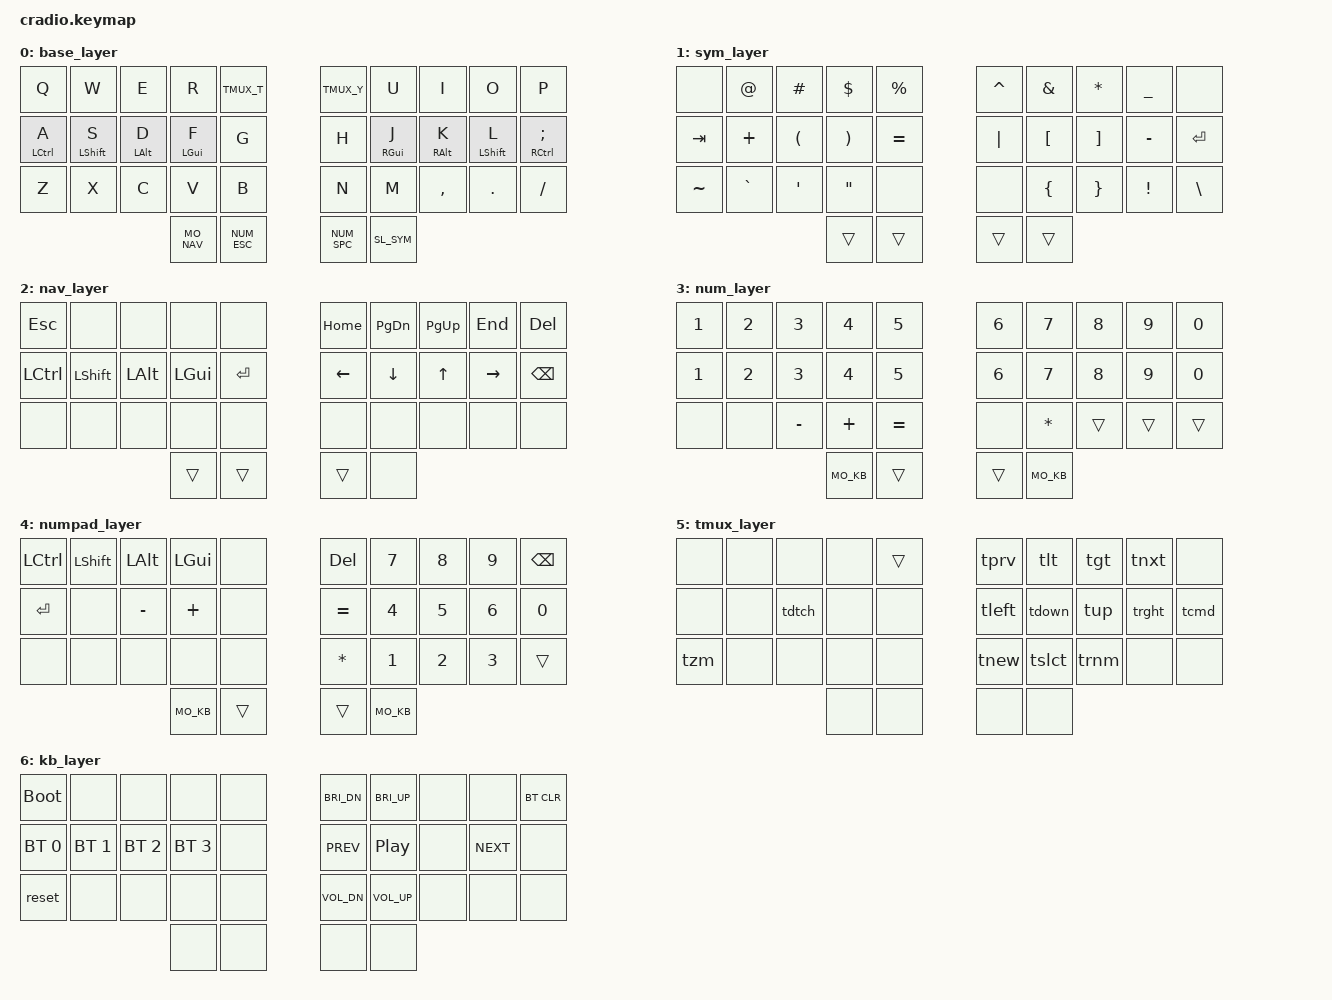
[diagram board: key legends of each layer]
/*
 * Copyright (c) 2020 The ZMK Contributors
 *
 * SPDX-License-Identifier: MIT
 */

#include <behaviors.dtsi>
#include <dt-bindings/zmk/keys.h>
#include <dt-bindings/zmk/bt.h>


// Constants
#define MO(layer) &mo layer
#define LTP(layer, kc) &lt layer kc
#define TO(layer) &to layer
#define TG(layer) &tog layer
#define SL(layer) &sl layer
#define SK(mod) &skq mod
#define _________ &trans
#define XXXXXXXXX &none

#define BOOT &bootloader
#define BTCLR &bt BT_CLR
#define BTNXT &bt BT_NXT
#define BTPRV &bt BT_PRV
#define BT_0 &bt BT_SEL 0
#define BT_1 &bt BT_SEL 1
#define BT_2 &bt BT_SEL 2
#define BT_3 &bt BT_SEL 3
#define MNEXT &kp C_NEXT
#define MPREV &kp C_PREV
#define MPLAY &kp C_PP
#define MVOLU &kp C_VOL_UP
#define MVOLD &kp C_VOL_DN
#define DBRIU &kp C_BRI_UP
#define DBRID &kp C_BRI_DN


// Helpers
#define LLT(layer, kc) &llt layer kc


// Layers
#define _BASE 0
#define _SYM 1
#define _NAV 2
#define _NUM 3
#define _NUMPAD 4
#define _TMUX 5
#define _KB 6


// Custom keycodes
#define SL_SYM SL(_SYM)
#define NUM_SPC LTP(_NUM, SPACE)
#define NUM_ESC LTP(_NUM, ESC)
#define TMUX_T LLT(_TMUX, T)
#define TMUX_Y LLT(_TMUX, Y)
#define MO_NAV MO(_NAV)
#define MO_KB MO(_KB)


// Homerow mods
#define HM_A &hm LCTRL A
#define HM_SEMI &hm RCTRL SEMI
#define HM_S &hm LSHFT S
#define HM_L &hm LSHFT L
#define HM_D &hm LALT D
#define HM_K &hm RALT K
#define HM_F &hm LGUI F
#define HM_J &hm RGUI J


// TMUX
#define TMUX_PREFIX &kp LC(B)
#define tm(NODELABEL, NODE, LABEL, USAGE) \
    NODELABEL: NODE { \
        compatible = "zmk,behavior-macro"; \
        label = LABEL; \
        #binding-cells = <0>; \
        wait-ms = <50>; \
        tap-ms = <40>; \
        bindings = <TMUX_PREFIX &kp USAGE>; \
    }


/ { 
    combos {
        compatible = "zmk,combos";

        combo_caps_word {
            timeout-ms = <50>;
            key-positions = <11 12 13>;
            bindings = <&caps_word>;
        };

        combo_esc {
            timeout-ms = <50>;
            key-positions = <16 17 18>;
            bindings = <&kp ESC>;
        };
    };

    behaviors {
        skq: sticky_key_quick_release {
            compatible = "zmk,behavior-sticky-key";
            label = "STICKY_KEY_QUICK_RELEASE";
            #binding-cells = <1>;
            bindings = <&kp>;
            release-after-ms = <750>;
            quick-release;
        };

        hm: homerow_mods {
            compatible = "zmk,behavior-hold-tap";
            label = "HOMEROW_MODS";
            #binding-cells = <2>;
            tapping-term-ms = <150>;
            flavor = "tap-preferred";
            bindings = <&kp>, <&kp>;
        };

        lhm: left_homerow_mods {
            compatible = "zmk,behavior-hold-tap";
            label = "LEFT_HOMEROW_MODS";
            #binding-cells = <2>;
            flavor = "tap-unless-interrupted";
            tapping-term-ms = <100>;                        // <---[[produces tap if held longer than tapping-term-ms]]
            bindings = <&kp>, <&kp>;
            hold-trigger-key-positions = <5 6 7 8 9 15 16 17 18 19 25 26 27 28 29>;    // <---[[right-hand keys]]
        };

        rhm: right_homerow_mods {
            compatible = "zmk,behavior-hold-tap";
            label = "RIGHT_HOMEROW_MODS";
            #binding-cells = <2>;
            flavor = "tap-unless-interrupted";
            tapping-term-ms = <100>;                        // <---[[produces tap if held longer than tapping-term-ms]]
            bindings = <&kp>, <&kp>;
            hold-trigger-key-positions = <0 1 2 3 4 10 11 12 13 14 20 21 22 23 24>;    // <---[[left-hand keys]]
        };

        llt: letter_layer_taps {
            compatible = "zmk,behavior-hold-tap";
            label = "LETTER_LAYER_TAPS";
            #binding-cells = <2>;
            tapping-term-ms = <200>;
            flavor = "tap-preferred";
            bindings = <&mo>, <&kp>;
        };

        // TMUX macro definitions
        tm(tnxt, tmux_next, "TMUX_NEXT", N);
        tm(tprv, tmux_prev, "TMUX_PREV", P);
        tm(tlt, tmux_lt, "TMUX_LT", LT);
        tm(tgt, tmux_gt, "TMUX_GT", GT);
        tm(tnew, tmux_new, "TMUX_NEW", C);
        tm(tslct, tmux_select, "TMUX_SELECT", LBKT);
        tm(tleft, tmux_left, "TMUX_LEFT", LEFT);
        tm(tdown, tmux_down, "TMUX_DOWN", DOWN);
        tm(tup, tmux_up, "TMUX_UP", UP);
        tm(trght, tmux_right, "TMUX_RIGHT", RIGHT);
        tm(tzm, tmux_zoom, "TMUX_ZOOM", Z);
        tm(tdtch, tmux_detach, "TMUX_DETACH", D);
        tm(tcmd, tmux_command, "TMUX_COMMAND", COLON);
        tm(trnm, tmux_rename, "TMUX_RENAME", COMMA);
    };

    keymap {
        compatible = "zmk,keymap";

        base_layer { bindings = <
          //┌─────────┬─────────┬─────────┬─────────┬─────────┐                            ┌─────────┬─────────┬─────────┬─────────┬─────────┐
             &kp Q     &kp W     &kp E     &kp R     TMUX_T                                 TMUX_Y    &kp U     &kp I     &kp O     &kp P 
          //├─────────┼─────────┼─────────┼─────────┼─────────┤                            ├─────────┼─────────┼─────────┼─────────┼─────────┤
             HM_A      HM_S      HM_D      HM_F      &kp G                                  &kp H     HM_J      HM_K      HM_L      HM_SEMI
          //├─────────┼─────────┼─────────┼─────────┼─────────┤                            ├─────────┼─────────┼─────────┼─────────┼─────────┤
             &kp Z     &kp X     &kp C     &kp V     &kp B                                  &kp N     &kp M     &kp COMMA &kp DOT   &kp FSLH
          //└─────────┴─────────┴─────────┴─────┬───┴─────┬───┼─────────┐        ┌─────────┼───┬─────┴───┬─────┴─────────┴─────────┴─────────┘
                                                 MO_NAV        NUM_ESC            NUM_SPC       SL_SYM
          //                                    └─────────┘   └─────────┘        └─────────┘   └─────────┘
        >; };

        sym_layer { bindings = <
          //┌─────────┬─────────┬─────────┬─────────┬─────────┐                            ┌─────────┬─────────┬─────────┬─────────┬─────────┐
             XXXXXXXXX &kp AT    &kp HASH  &kp DLLR  &kp PRCNT                              &kp CARET &kp AMPS  &kp STAR  &kp UNDER XXXXXXXXX
          //├─────────┼─────────┼─────────┼─────────┼─────────┤                            ├─────────┼─────────┼─────────┼─────────┼─────────┤
             &kp TAB   &kp PLUS  &kp LPAR  &kp RPAR  &kp EQUAL                              &kp PIPE  &kp LBKT  &kp RBKT  &kp MINUS &kp RET
          //├─────────┼─────────┼─────────┼─────────┼─────────┤                            ├─────────┼─────────┼─────────┼─────────┼─────────┤
             &kp TILDE &kp GRAVE &kp SQT   &kp DQT   XXXXXXXXX                              XXXXXXXXX &kp LBRC  &kp RBRC  &kp EXCL  &kp BSLH
          //└─────────┴─────────┴─────────┴─────┬───┴─────┬───┼─────────┐        ┌─────────┼───┬─────┴───┬─────┴─────────┴─────────┴─────────┘
                                                 _________     _________          _________     _________
          //                                    └─────────┘   └─────────┘        └─────────┘   └─────────┘
        >; };

        nav_layer { bindings = <
          //┌─────────┬─────────┬─────────┬─────────┬─────────┐                            ┌─────────┬─────────┬─────────┬─────────┬─────────┐
             &kp ESC   XXXXXXXXX XXXXXXXXX XXXXXXXXX XXXXXXXXX                              &kp HOME  &kp PG_DN &kp PG_UP &kp END   &kp DEL
          //├─────────┼─────────┼─────────┼─────────┼─────────┤                            ├─────────┼─────────┼─────────┼─────────┼─────────┤
             &kp LCTRL &kp LSHFT &kp LALT  &kp LGUI  &kp RET                                &kp LEFT  &kp DOWN  &kp UP    &kp RIGHT &kp BSPC
          //├─────────┼─────────┼─────────┼─────────┼─────────┤                            ├─────────┼─────────┼─────────┼─────────┼─────────┤
             XXXXXXXXX XXXXXXXXX XXXXXXXXX XXXXXXXXX XXXXXXXXX                              XXXXXXXXX XXXXXXXXX XXXXXXXXX XXXXXXXXX XXXXXXXXX
          //└─────────┴─────────┴─────────┴─────┬───┴─────┬───┼─────────┐        ┌─────────┼───┬─────┴───┬─────┴─────────┴─────────┴─────────┘
                                                 _________     _________          _________     XXXXXXXXX
          //                                    └─────────┘   └─────────┘        └─────────┘   └─────────┘
        >; };

        num_layer { bindings = <
          //┌─────────┬─────────┬─────────┬─────────┬─────────┐                            ┌─────────┬─────────┬─────────┬─────────┬─────────┐
             &kp N1    &kp N2    &kp N3    &kp N4    &kp N5                                 &kp N6    &kp N7    &kp N8    &kp N9    &kp N0   
          //├─────────┼─────────┼─────────┼─────────┼─────────┤                            ├─────────┼─────────┼─────────┼─────────┼─────────┤
             &kp N1    &kp N2    &kp N3    &kp N4    &kp N5                                 &kp N6    &kp N7    &kp N8    &kp N9    &kp N0   
          //├─────────┼─────────┼─────────┼─────────┼─────────┤                            ├─────────┼─────────┼─────────┼─────────┼─────────┤
             XXXXXXXXX XXXXXXXXX &kp MINUS &kp PLUS  &kp EQUAL                              XXXXXXXXX &kp STAR  _________ _________ _________
          //└─────────┴─────────┴─────────┴─────┬───┴─────┬───┼─────────┐        ┌─────────┼───┬─────┴───┬─────┴─────────┴─────────┴─────────┘
                                                 MO_KB         _________          _________     MO_KB
          //                                    └─────────┘   └─────────┘        └─────────┘   └─────────┘
        >; };

        numpad_layer { bindings = <
          //┌─────────┬─────────┬─────────┬─────────┬─────────┐                            ┌─────────┬─────────┬─────────┬─────────┬─────────┐
             &kp LCTRL &kp LSHFT &kp LALT  &kp LGUI  XXXXXXXXX                              &kp DEL   &kp N7    &kp N8    &kp N9    &kp BSPC
          //├─────────┼─────────┼─────────┼─────────┼─────────┤                            ├─────────┼─────────┼─────────┼─────────┼─────────┤
             &kp RET   XXXXXXXXX &kp MINUS &kp PLUS  XXXXXXXXX                              &kp EQUAL &kp N4    &kp N5    &kp N6    &kp N0
          //├─────────┼─────────┼─────────┼─────────┼─────────┤                            ├─────────┼─────────┼─────────┼─────────┼─────────┤
             XXXXXXXXX XXXXXXXXX XXXXXXXXX XXXXXXXXX XXXXXXXXX                              &kp STAR  &kp N1    &kp N2    &kp N3    _________
          //└─────────┴─────────┴─────────┴─────┬───┴─────┬───┼─────────┐        ┌─────────┼───┬─────┴───┬─────┴─────────┴─────────┴─────────┘
                                                 MO_KB         _________          _________     MO_KB
          //                                    └─────────┘   └─────────┘        └─────────┘   └─────────┘
        >; };

        tmux_layer { bindings = <
          //┌─────────┬─────────┬─────────┬─────────┬─────────┐                            ┌─────────┬─────────┬─────────┬─────────┬─────────┐
             XXXXXXXXX XXXXXXXXX XXXXXXXXX XXXXXXXXX _________                              &tprv     &tlt      &tgt      &tnxt     XXXXXXXXX
          //├─────────┼─────────┼─────────┼─────────┼─────────┤                            ├─────────┼─────────┼─────────┼─────────┼─────────┤
             XXXXXXXXX XXXXXXXXX &tdtch    XXXXXXXXX XXXXXXXXX                              &tleft    &tdown    &tup      &trght    &tcmd
          //├─────────┼─────────┼─────────┼─────────┼─────────┤                            ├─────────┼─────────┼─────────┼─────────┼─────────┤
             &tzm      XXXXXXXXX XXXXXXXXX XXXXXXXXX XXXXXXXXX                              &tnew     &tslct    &trnm     XXXXXXXXX XXXXXXXXX
          //└─────────┴─────────┴─────────┴─────┬───┴─────┬───┼─────────┐        ┌─────────┼───┬─────┴───┬─────┴─────────┴─────────┴─────────┘
                                                 XXXXXXXXX     XXXXXXXXX          XXXXXXXXX     XXXXXXXXX
          //                                    └─────────┘   └─────────┘        └─────────┘   └─────────┘
        >; };

        kb_layer { bindings = <
          //┌─────────┬─────────┬─────────┬─────────┬─────────┐                            ┌─────────┬─────────┬─────────┬─────────┬─────────┐
             BOOT      XXXXXXXXX XXXXXXXXX XXXXXXXXX XXXXXXXXX                              DBRID     DBRIU     XXXXXXXXX XXXXXXXXX BTCLR
          //├─────────┼─────────┼─────────┼─────────┼─────────┤                            ├─────────┼─────────┼─────────┼─────────┼─────────┤
             BT_0      BT_1      BT_2      BT_3      XXXXXXXXX                              MPREV     MPLAY     XXXXXXXXX MNEXT     XXXXXXXXX
          //├─────────┼─────────┼─────────┼─────────┼─────────┤                            ├─────────┼─────────┼─────────┼─────────┼─────────┤
             &reset    XXXXXXXXX XXXXXXXXX XXXXXXXXX XXXXXXXXX                              MVOLD     MVOLU     XXXXXXXXX XXXXXXXXX XXXXXXXXX
          //└─────────┴─────────┴─────────┴─────┬───┴─────┬───┼─────────┐        ┌─────────┼───┬─────┴───┬─────┴─────────┴─────────┴─────────┘
                                                 XXXXXXXXX     XXXXXXXXX          XXXXXXXXX     XXXXXXXXX
          //                                    └─────────┘   └─────────┘        └─────────┘   └─────────┘
        >; };
    };
};
